# STM32MP21_CM33 register map
File version: 0.4
CPU: CM33 r0p1, little endian, MPU, FPU, vendor SysTick, 8 interrupt priority bits
Registers are 32-bit, read-write, reset 0x0 unless marked. A register's access mark holds for its fields unless they carry their own. Offsets are from the block's base; [hi:lo] are bit positions; {n}, {i} and the like mark numbered series.

## DCMI — DCMI address block description
Base 0x404A0000
Same registers: DCMI_S 0x504A0000
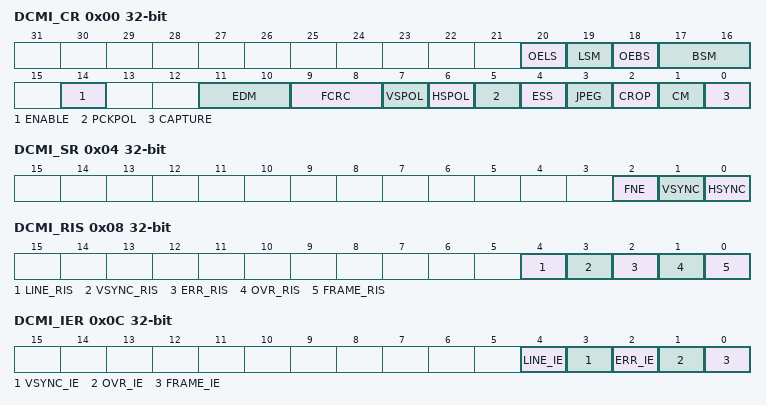
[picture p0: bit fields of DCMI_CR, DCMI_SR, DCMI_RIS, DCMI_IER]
0x00 DCMI_CR — DCMI control register
  [20] OELS — Odd/Even Line Select (Line Select Start) This bit works in conjunction with the LSM field (LSM = 1).
    0=Interface captures first line after the frame start, second one being dropped; 1=Interface captures second line from the frame start, first one being dropped
  [19] LSM — Line Select mode
    0=Interface captures all received lines; 1=Interface captures one line out of two
  [18] OEBS — Odd/Even Byte Select (Byte Select Start) This bit works in conjunction with BSM field (BSM different 00).
    0=Interface captures first data (byte or double byte) from the frame/line start, second one being dropped; 1=Interface captures second data (byte or double byte) from the frame/line start, first one being dropped
  [17:16] BSM — Byte Select mode Note: This mode only works for EDM[1:0]=00. For all other EDM values, this field must be programmed to the reset value.
    0=Interface captures all received data; 1=Interface captures every other byte from the received data; 2=Interface captures one byte out of four; 3=Interface captures two bytes out of four
  [14] ENABLE — DCMI enable Note: The DCMI configuration registers must be programmed correctly before enabling this bit.
    0=DCMI disabled; 1=DCMI enabled
  [11:10] EDM — Extended data mode
    0=Interface captures 8-bit data on every pixel clock; 1=Interface captures 10-bit data on every pixel clock; 2=Interface captures 12-bit data on every pixel clock; 3=Interface captures 14-bit data on every pixel clock
  [9:8] FCRC — Frame capture rate control These bits define the frequency of frame capture. They are meaningful only in Continuous grab mode. They are ignored in snapshot mode.
    0=All frames are captured; 1=Every alternate frame captured (50% bandwidth reduction); 2=One frame out of four captured (75% bandwidth reduction)
  [7] VSPOL — Vertical synchronization polarity This bit indicates the level on the DCMI_VSYNC pin when the data are not valid on the parallel interface.
    0=DCMI_VSYNC active low; 1=DCMI_VSYNC active high
  [6] HSPOL — Horizontal synchronization polarity This bit indicates the level on the DCMI_HSYNC pin when the data are not valid on the parallel interface.
    0=DCMI_HSYNC active low; 1=DCMI_HSYNC active high
  [5] PCKPOL — Pixel clock polarity This bit configures the capture edge of the pixel clock.
    0=Falling edge active; 1=Rising edge active
  [4] ESS — Embedded synchronization select Note: Valid only for 8-bit parallel data. HSPOL/VSPOL are ignored when the ESS bit is set. This bit is disabled in JPEG mode.
    0=Hardware synchronization data capture (frame/line start/stop) is synchronized with the DCMI_HSYNC/DCMI_VSYNC signals; 1=Embedded synchronization data capture is synchronized with synchronization codes embedded in the data flow
  [3] JPEG — JPEG format
    0=Uncompressed video format; 1=This bit is used for JPEG data transfers. The DCMI_HSYNC signal is used as data enable. The crop and embedded synchronization features (ESS bit) cannot be used in this mode.
  [2] CROP — Crop feature
    0=The full image is captured. In this case the total number of bytes in an image frame must be a multiple of four.; 1=Only the data inside the window specified by the crop register is captured. If the size of the crop window exceeds the picture size, then only the picture size is captured.
  [1] CM — Capture mode
    0=Continuous grab mode - The received data are transferred into the destination memory through the DMA. The buffer location and mode (linear or circular buffer) is controlled through the system DMA.; 1=Snapshot mode (single frame) - Once activated, the interface waits for the start of frame and then transfers a single frame through the DMA. At the end of the frame, the CAPTURE bit is automatically reset.
  [0] CAPTURE — Capture enable The camera interface waits for the first start of frame, then a DMA request is generated to transfer the received data into the destination memory. In snapshot mode, the CAPTURE bit is automatically cleared at the end of the first frame received. In continuous grab mode, if the software clears this bit while a capture is ongoing, the bit is effectively cleared after the frame end. Note: The DMA controller and all DCMI configuration registers must be programmed correctly before enabling this bit.
    0=Capture disabled; 1=Capture enabled
0x04 DCMI_SR ro — DCMI status register
  [2] FNE — FIFO not empty This bit gives the status of the FIFO.
    1=FIFO contains valid data; 0=FIFO empty
  [1] VSYNC — Vertical synchronization This bit gives the state of the DCMI_VSYNC pin with the correct programmed polarity. When embedded synchronization codes are used, the meaning of this bit is the following: In case of embedded synchronization, this bit is meaningful only if the CAPTURE bit in DCMI_CR is set.
    0=active frame; 1=synchronization between frames
  [0] HSYNC — Horizontal synchronization This bit gives the state of the DCMI_HSYNC pin with the correct programmed polarity. When embedded synchronization codes are used, the meaning of this bit is the following: In case of embedded synchronization, this bit is meaningful only if the CAPTURE bit in DCMI_CR is set.
    0=active line; 1=synchronization between lines
0x08 DCMI_RIS ro — DCMI raw interrupt status register
  [4] LINE_RIS — Line raw interrupt status This bit gets set when the DCMI_HSYNC signal changes from the inactive state to the active state. It goes high even if the line is not valid. In the case of embedded synchronization, this bit is set only if the CAPTURE bit in DCMI_CR is set. It is cleared by setting the LINE_ISC bit of the DCMI_ICR register.
  [3] VSYNC_RIS — DCMI_VSYNC raw interrupt status This bit is set when the DCMI_VSYNC signal changes from the inactive state to the active state. In the case of embedded synchronization, this bit is set only if the CAPTURE bit is set in DCMI_CR. It is cleared by setting the VSYNC_ISC bit of the DCMI_ICR register.
  [2] ERR_RIS — Synchronization error raw interrupt status This bit is valid only in the embedded synchronization mode. It is cleared by setting the ERR_ISC bit of the DCMI_ICR register. Note: This bit is available only in embedded synchronization mode.
    0=No synchronization error detected; 1=Embedded synchronization characters are not received in the correct order
  [1] OVR_RIS — Overrun raw interrupt status The bit is cleared by setting the OVR_ISC bit of the DCMI_ICR register.
    0=No data buffer overrun occurred; 1=A data buffer overrun occurred and the data FIFO is corrupted
  [0] FRAME_RIS — Capture complete raw interrupt status This bit is set when a frame or window has been captured. In case of a cropped window, this bit is set at the end of line of the last line in the crop. It is set even if the captured frame is empty (for example window cropped outside the frame). The bit is cleared by setting the FRAME_ISC bit of the DCMI_ICR register.
    0=No new capture; 1=A frame has been captured
0x0C DCMI_IER — DCMI interrupt enable register
  [4] LINE_IE — Line interrupt enable
    0=No interrupt generation when the line is received; 1=An Interrupt is generated when a line has been completely received
  [3] VSYNC_IE — DCMI_VSYNC interrupt enable The active state of the DCMI_VSYNC signal is defined by the VSPOL bit.
    0=No interrupt generation; 1=An interrupt is generated on each DCMI_VSYNC transition from the inactive to the active state
  [2] ERR_IE — Synchronization error interrupt enable Note: This bit is available only in embedded synchronization mode.
    0=No interrupt generation; 1=An interrupt is generated if the embedded synchronization codes are not received in the correct order
  [1] OVR_IE — Overrun interrupt enable
    0=No interrupt generation; 1=An interrupt is generated if the DMA was not able to transfer the last data before new data (32-bit) are received
  [0] FRAME_IE — Capture complete interrupt enable
    0=No interrupt generation; 1=An interrupt is generated at the end of each received frame/crop window (in crop mode)
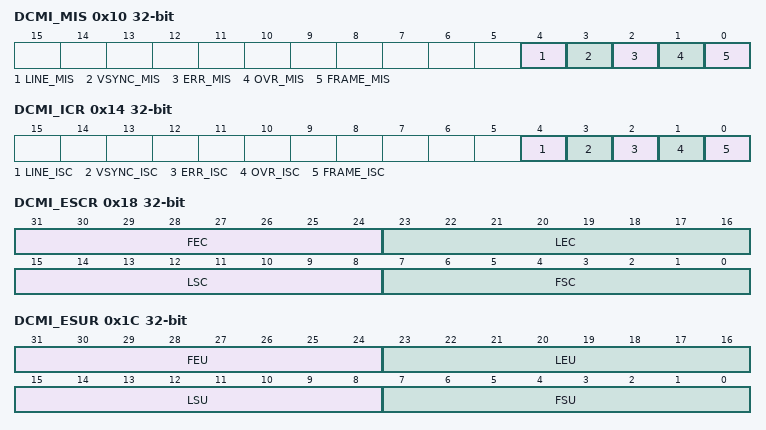
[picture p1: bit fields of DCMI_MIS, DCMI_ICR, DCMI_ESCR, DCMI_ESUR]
0x10 DCMI_MIS ro — DCMI masked interrupt status register
  [4] LINE_MIS — Line masked interrupt status This bit gives the status of the masked line interrupt.
    0=No interrupt generation when the line is received; 1=An Interrupt is generated when a line has been completely received and the LINE_IE bit is set in DCMI_IER
  [3] VSYNC_MIS — VSYNC masked interrupt status This bit gives the status of the masked VSYNC interrupt. The active state of the DCMI_VSYNC signal is defined by the VSPOL bit.
    0=No interrupt is generated on DCMI_VSYNC transitions; 1=An interrupt is generated on each DCMI_VSYNC transition from the inactive to the active state and the VSYNC_IE bit is set in DCMI_IER
  [2] ERR_MIS — Synchronization error masked interrupt status This bit gives the status of the masked synchronization error interrupt. Note: This bit is available only in embedded synchronization mode.
    0=No interrupt is generated on a synchronization error; 1=An interrupt is generated if the embedded synchronization codes are not received in the correct order and the ERR_IE bit in DCMI_IER is set
  [1] OVR_MIS — Overrun masked interrupt status This bit gives the status of the masked overflow interrupt.
    0=No interrupt is generated on overrun; 1=An interrupt is generated if the DMA was not able to transfer the last data before new data (32-bit) are received and the OVR_IE bit is set in DCMI_IER
  [0] FRAME_MIS — Capture complete masked interrupt status This bit gives the status of the masked capture complete interrupt
    0=No interrupt is generated after a complete capture; 1=An interrupt is generated at the end of each received frame/crop window (in crop mode) and the FRAME_IE bit is set in DCMI_IER
0x14 DCMI_ICR wo — DCMI interrupt clear register
  [4] LINE_ISC — line interrupt status clear Setting this bit clears the LINE_RIS flag in the DCMI_RIS register.
  [3] VSYNC_ISC — Vertical Synchronization interrupt status clear Setting this bit clears the VSYNC_RIS flag in the DCMI_RIS register.
  [2] ERR_ISC — Synchronization error interrupt status clear Setting this bit clears the ERR_RIS flag in the DCMI_RIS register. Note: This bit is available only in embedded synchronization mode.
  [1] OVR_ISC — Overrun interrupt status clear Setting this bit clears the OVR_RIS flag in the DCMI_RIS register.
  [0] FRAME_ISC — Capture complete interrupt status clear Setting this bit clears the FRAME_RIS flag in the DCMI_RIS register.
0x18 DCMI_ESCR — DCMI embedded synchronization code register
  [31:24] FEC — Frame end delimiter code This byte specifies the code of the frame end delimiter. The code consists of 4 bytes in the form of 0xFF, 0x00, 0x00, FEC. If FEC is programmed to 0xFF, all the unused codes (0xFF0000XY) are interpreted as frame end delimiters.
  [23:16] LEC — Line end delimiter code This byte specifies the code of the line end delimiter. The code consists of 4 bytes in the form of 0xFF, 0x00, 0x00, LEC.
  [15:8] LSC — Line start delimiter code This byte specifies the code of the line start delimiter. The code consists of 4 bytes in the form of 0xFF, 0x00, 0x00, LSC.
  [7:0] FSC — Frame start delimiter code This byte specifies the code of the frame start delimiter. The code consists of 4 bytes in the form of 0xFF, 0x00, 0x00, FSC. If FSC is programmed to 0xFF, no frame start delimiter is detected. But, the first occurrence of LSC after an FEC code is interpreted as a start of frame delimiter.
0x1C DCMI_ESUR — DCMI embedded synchronization unmask register
  [31:24] FEU — Frame end delimiter unmask This byte specifies the mask to be applied to the code of the frame end delimiter.
    0=The corresponding bit in the FEC byte in DCMI_ESCR is masked while comparing the frame end delimiter with the received data; 1=The corresponding bit in the FEC byte in DCMI_ESCR is compared while comparing the frame end delimiter with the received data
  [23:16] LEU — Line end delimiter unmask This byte specifies the mask to be applied to the code of the line end delimiter.
    0=The corresponding bit in the LEC byte in DCMI_ESCR is masked while comparing the line end delimiter with the received data; 1=The corresponding bit in the LEC byte in DCMI_ESCR is compared while comparing the line end delimiter with the received data
  [15:8] LSU — Line start delimiter unmask This byte specifies the mask to be applied to the code of the line start delimiter.
    0=The corresponding bit in the LSC byte in DCMI_ESCR is masked while comparing the line start delimiter with the received data; 1=The corresponding bit in the LSC byte in DCMI_ESCR is compared while comparing the line start delimiter with the received data
  [7:0] FSU — Frame start delimiter unmask This byte specifies the mask to be applied to the code of the frame start delimiter.
    0=The corresponding bit in the FSC byte in DCMI_ESCR is masked while comparing the frame start delimiter with the received data; 1=The corresponding bit in the FSC byte in DCMI_ESCR is compared while comparing the frame start delimiter with the received data
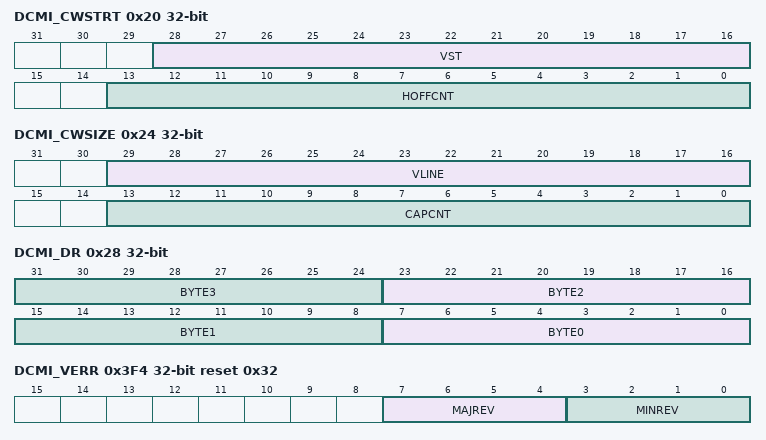
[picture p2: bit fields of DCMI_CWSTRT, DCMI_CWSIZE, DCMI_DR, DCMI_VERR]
0x20 DCMI_CWSTRT — DCMI crop window start
  [28:16] VST — Vertical start line count The image capture starts with this line number. Previous line data are ignored. ....
    0=line 1; 1=line 2; 2=line 3
  [13:0] HOFFCNT — Horizontal offset count This value gives the number of pixel clocks to count before starting a capture.
0x24 DCMI_CWSIZE — DCMI crop window size
  [29:16] VLINE — Vertical line count This value gives the number of lines to be captured from the starting point. ....
    0=1 line; 1=2 lines; 2=3 lines
  [13:0] CAPCNT — Capture count This value gives the number of pixel clocks to be captured from the starting point on the same line. It value must corresponds to word-aligned data for different widths of parallel interfaces. ....
    0=1 pixel; 1=2 pixels; 2=3 pixels
0x28 DCMI_DR ro — DCMI data register
  [8n+7:8n] BYTE{n} (n=0..3) — Data byte {n}
0x3F0 DCMI_HWCFGR ro reset 0x1 — DCMI hardware configuration register
  [3:0] FIFO_8 — FIFO size
0x3F4 DCMI_VERR ro reset 0x32 — DCMI version register
  [7:4] MAJREV — IP version, major revision information
  [3:0] MINREV — IP version, minor revision information
0x3F8 DCMI_IPIDR ro reset 0x160011 — DCMI identification register
  [31:0] IP_ID — 0x0016 0011
0x3FC DCMI_SIDR ro reset 0xA3C5DD01 — DCMI size identification register
  [31:0] SID — Size identification code This bit field returns the size identification code of the DCMI peripheral as defined below: Bits[31:8] = 0xA3C5DD (fixed code) Bits[7:0] = 0x01 (1-Kbyte address decoding)
